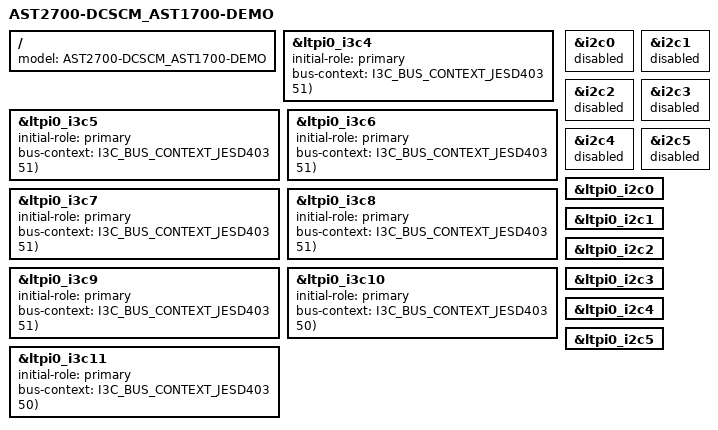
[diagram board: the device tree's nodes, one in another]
// SPDX-License-Identifier: GPL-2.0-or-later

/dts-v1/;

#include "ast2700-dcscm.dts"
#include "aspeed-ltpi0.dtsi"

/ {
	model = "AST2700-DCSCM_AST1700-DEMO";
};

#define JESD300_SPD_I3C_MODE(bus, index, addr) \
spd_ ## bus ## _ ## index: spd@addr,4cc5118 ## index ## 000 { \
	reg = <0x ## addr 0x4cc 0x5118 ## index ## 000>; \
	assigned-address = <0x ## addr>; \
	dcr = /bits/ 8 <0xda>; \
	bcr = /bits/ 8 <0x6>; \
}

#include <dt-bindings/i3c/i3c.h>

&ltpi0_i3c4 {
	initial-role = "primary";
	status = "okay";

	bus-context = /bits/ 8 <I3C_BUS_CONTEXT_JESD403>;
	JESD300_SPD_I3C_MODE(4, 1, 51);
};

&ltpi0_i3c5 {
	initial-role = "primary";
	status = "okay";

	bus-context = /bits/ 8 <I3C_BUS_CONTEXT_JESD403>;
	JESD300_SPD_I3C_MODE(5, 1, 51);
};

&ltpi0_i3c6 {
	initial-role = "primary";
	status = "okay";

	bus-context = /bits/ 8 <I3C_BUS_CONTEXT_JESD403>;
	JESD300_SPD_I3C_MODE(6, 1, 51);
};

&ltpi0_i3c7 {
	initial-role = "primary";
	status = "okay";

	bus-context = /bits/ 8 <I3C_BUS_CONTEXT_JESD403>;
	JESD300_SPD_I3C_MODE(7, 1, 51);
};

&ltpi0_i3c8 {
	initial-role = "primary";
	status = "okay";

	bus-context = /bits/ 8 <I3C_BUS_CONTEXT_JESD403>;
	JESD300_SPD_I3C_MODE(8, 1, 51);
};

&ltpi0_i3c9 {
	initial-role = "primary";
	status = "okay";

	bus-context = /bits/ 8 <I3C_BUS_CONTEXT_JESD403>;
	JESD300_SPD_I3C_MODE(9, 1, 51);
};

&ltpi0_i3c10 {
	initial-role = "primary";
	status = "okay";

	bus-context = /bits/ 8 <I3C_BUS_CONTEXT_JESD403>;
	JESD300_SPD_I3C_MODE(10, 0, 50);
};

&ltpi0_i3c11 {
	initial-role = "primary";
	status = "okay";

	bus-context = /bits/ 8 <I3C_BUS_CONTEXT_JESD403>;
	JESD300_SPD_I3C_MODE(11, 0, 50);
};

&i2c0 {
	status = "disabled";
};

&i2c1 {
	status = "disabled";
};

&i2c2 {
	status = "disabled";
};

&i2c3 {
	status = "disabled";
};

&i2c4 {
	status = "disabled";
};

&i2c5 {
	status = "disabled";
};

&ltpi0_i2c0 {
	/* SMB_PMBUS1_SCM */
	status = "okay";
};

&ltpi0_i2c1 {
	/* SMB_PMBUS2_SCM */
	status = "okay";
};

&ltpi0_i2c2 {
	status = "okay";
};

&ltpi0_i2c3 {
	status = "okay";
};

&ltpi0_i2c4 {
	status = "okay";
};

&ltpi0_i2c5 {
	status = "okay";
};
